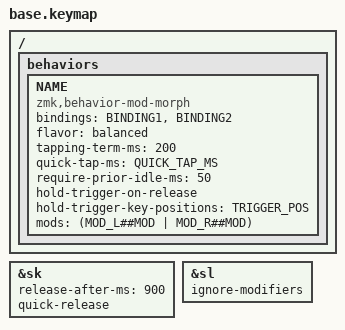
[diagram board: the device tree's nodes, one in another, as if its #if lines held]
#include <behaviors.dtsi>
#include <dt-bindings/zmk/keys.h>
#include <dt-bindings/zmk/rgb.h>
#include <zmk-helpers/helper.h> // Requires zmk-helpers module.

#ifdef CONFIG_WIRELESS
  #include <dt-bindings/zmk/bt.h>
  #include <dt-bindings/zmk/outputs.h>
  #define _BT_SEL_KEYS_                                                        \
      &bt BT_CLR &bt BT_SEL 0 &bt BT_SEL 1 &bt BT_SEL 2 &bt BT_SEL 3
#else
  #define _BT_SEL_KEYS_ &trans &trans &trans &trans &trans
#endif

#define _MEDIA_KEYS_                                                          \
    &kp C_PREVIOUS &kp C_PLAY_PAUSE &kp C_NEXT


#define _VOLUME_KEYS_                                                          \
    &kp C_VOLUME_DOWN &kp C_VOLUME_UP

#define _BRIGHTNESS_KEYS_                                                      \
    &kp C_BRIGHTNESS_DEC &kp C_BRIGHTNESS_INC

#define DEF 0
#define NAV 1
#define NUM 2
#define SYS 3

#define XXX &none
#define ___ &trans

#define KEYS_L LT0 LT1 LT2 LT3 LT4 LM0 LM1 LM2 LM3 LM4 LB0 LB1 LB2 LB3 LB4
#define KEYS_R RT0 RT1 RT2 RT3 RT4 RM0 RM1 RM2 RM3 RM4 RB0 RB1 RB2 RB3 RB4
#define THUMBS LH2 LH1 LH0 RH0 RH1 RH2

#define QUICK_TAP_MS 175

#define MAKE_HRM(NAME, HOLD, TAP, TRIGGER_POS)                                 \
  ZMK_HOLD_TAP(NAME, bindings = <HOLD>, <TAP>; flavor = "balanced";            \
               tapping-term-ms = <200>; quick-tap-ms = <QUICK_TAP_MS>;         \
               require-prior-idle-ms = <50>; hold-trigger-on-release;          \
               hold-trigger-key-positions = <TRIGGER_POS>;)

// Hack: Make HRM combos tap-only (cf, ZMK issue #544).
#define ZMK_COMBO_8(NAME, TAP, POS, LAYERS, COMBO_MS, IDLE_MS, HOLD, SIDE)     \
  MAKE_HRM(hm_combo_##NAME, &kp, TAP, SIDE THUMBS)                             \
  ZMK_COMBO_6(NAME, &hm_combo_##NAME HOLD 0, POS, LAYERS, COMBO_MS, IDLE_MS)

// Define mod-morph with a *single* mod trigger for less repetition.
#define SIMPLE_MORPH(NAME, MOD, BINDING1, BINDING2)                            \
  ZMK_MOD_MORPH(NAME, mods = <(MOD_L##MOD | MOD_R##MOD)>;                      \
                bindings = <BINDING1>, <BINDING2>;)

#define SHIFT_MORPH(NAME, BINDING1, BINDING2)                                  \
  SIMPLE_MORPH(NAME, SFT, BINDING1, BINDING2)

#ifndef ZMK_BASE_LAYER
  #define ZMK_BASE_LAYER(name, LT, RT, LM, RM, LB, RB, LH, RH)                 \
      ZMK_LAYER(name, LT RT LM RM LB RB LH RH)
#endif


&sk {
  release-after-ms = <900>;
  quick-release;
};

&sl { // Allow sticky mods to chord across sticky layers.
  ignore-modifiers;
};

MAKE_HRM(hml, &kp, &kp, KEYS_R THUMBS) // Left-hand HRMs.
MAKE_HRM(hmr, &kp, &kp, KEYS_L THUMBS) // Right-hand HRMs.

#include "morphs.dtsi" // Must be sourced after simple & shift morph.
#include "combos.dtsi" // Must be sourced after HRM-combo hack.

// HRM shortcuts left hand
#define HML_S(key) &hml LSHFT key
#define HML_G(key) &hml LCMD key
#define HML_A(key) &hml LALT key
#define HML_C(key) &hml LCTRL key

// HRM shortcuts right hand
#define HMR_S(key) &hmr RSHFT key
#define HMR_G(key) &hmr RCMD key
#define HMR_A(key) &hmr RALT key
#define HMR_C(key) &hmr LCTRL key

// Misc aliases
#define MEH       LS(LC(LALT))
#define HPR       LS(LC(LG(LALT)))
#define CANCEL    &kp K_CANCEL            // Cancel caps-word & auto-layers.

#define NAV_BSPC  &mt LA(BSPC) BSPC  // Tap: bspc  | Long-tap: delete word bwd.
#define NAV_DEL   &mt LA(DEL)  DEL   // Tap: del   | Long-tap: delete word fwd.

ZMK_CONDITIONAL_LAYER(sys, NAV NUM, SYS) // FN + NUM --> SYS.

ZMK_BASE_LAYER(Base,
//╭─────────────┬─────────────┬─────────────┬─────────────┬─────────────╮ ╭─────────────┬─────────────┬─────────────┬─────────────┬─────────────╮
    &kp Q         &kp W         &kp E         &kp R         &kp T       ,   &kp Y         &kp U         &kp I         &kp O         &kp P       ,
//├─────────────┼─────────────┼─────────────┼─────────────┼─────────────┤ ├─────────────┼─────────────┼─────────────┼─────────────┼─────────────┤
    HML_C(A)      HML_A(S)      HML_G(D)      HML_S(F)      &kp G       ,   &kp H         HMR_S(J)      HMR_G(K)      HMR_A(L)      HMR_C(SQT)  ,
//├─────────────┼─────────────┼─────────────┼─────────────┼─────────────┤ ├─────────────┼─────────────┼─────────────┼─────────────┼─────────────┤
    &kp Z         &kp X        &kp C          &kp V         &kp B       ,   &kp N         &kp M         &comma_semi   &dot_colon    &qmark_emark,
//╰─────────────┼─────────────┴─────────────┼─────────────┼─────────────┤ ├─────────────┼─────────────┼─────────────┴───────────────────────────╯
                               &kp ESC        &mt MEH TAB   &lt NAV SPACE,  &lt NUM BSPC  &mt HPR RET   CANCEL
//                            ╰─────────────┴─────────────┴─────────────╯ ╰─────────────┴─────────────┴─────────────╯
)

ZMK_BASE_LAYER(Nav,
//╭─────────────┬─────────────┬─────────────┬─────────────┬─────────────╮ ╭─────────────┬─────────────┬─────────────┬─────────────┬─────────────╮
    ___           NAV_BSPC      &kp TAB       NAV_DEL       ___         ,   &kp PG_UP     ___           ___           ___           ___         ,
//├─────────────┼─────────────┼─────────────┼─────────────┼─────────────┤ ├─────────────┼─────────────┼─────────────┼─────────────┼─────────────┤
    &sk LCTRL     &sk LALT      &sk LGUI      &sk LSHFT     ___         ,   &kp LEFT      &kp DOWN      &kp UP        &kp RIGHT     &kp RET     ,
//├─────────────┼─────────────┼─────────────┼─────────────┼─────────────┤ ├─────────────┼─────────────┼─────────────┼─────────────┼─────────────┤
    ___           ___           &sk MEH       &sk HPR       ___         ,   &kp PG_DN     ___           ___           ___           ___         ,
//╰─────────────┼─────────────┴─────────────┼─────────────┼─────────────┤ ├─────────────┼─────────────┼─────────────┴───────────────────────────╯
                                ___           ___           ___         ,   ___           ___           ___
//                            ╰─────────────┴─────────────┴─────────────╯ ╰─────────────┴─────────────┴─────────────╯
)


ZMK_BASE_LAYER(Num,
//╭─────────────┬─────────────┬─────────────┬─────────────┬─────────────╮ ╭─────────────┬─────────────┬─────────────┬─────────────┬─────────────╮
    ___           &kp N7        &kp N8        &kp N9        ___         ,   ___           &kp N7        &kp N8        &kp N9        ___         ,
//├─────────────┼─────────────┼─────────────┼─────────────┼─────────────┤ ├─────────────┼─────────────┼─────────────┼─────────────┼─────────────┤
    HML_C(N0)     HML_A(N4)     HML_G(N5)     HML_S(N6)     ___         ,   ___           HMR_S(N4)     HMR_G(N5)     HMR_A(N6)     HMR_C(N0)   ,
//├─────────────┼─────────────┼─────────────┼─────────────┼─────────────┤ ├─────────────┼─────────────┼─────────────┼─────────────┼─────────────┤
    ___           &kp N1        &kp N2        &kp N3        ___         ,   ___           &kp N1        &kp N2        &kp N3        ___         ,
//╰─────────────┼─────────────┴─────────────┼─────────────┼─────────────┤ ├─────────────┼─────────────┼─────────────┴───────────────────────────╯
                                &sk LCTRL     &sk LALT      &sk LGUI    ,   ___           ___           ___
//                            ╰─────────────┴─────────────┴─────────────╯ ╰─────────────┴─────────────┴─────────────╯
)

ZMK_BASE_LAYER(Sys,
//╭─────────────┬─────────────┬─────────────┬─────────────┬─────────────╮ ╭─────────────┬─────────────┬─────────────┬─────────────┬─────────────╮
                               _BT_SEL_KEYS_                            ,   ___                         _MEDIA_KEYS_                ___         ,
//├─────────────┼─────────────┼─────────────┼─────────────┼─────────────┤ ├─────────────┼─────────────┼─────────────┼─────────────┼─────────────┤
    ___           ___           ___           ___           &bootloader ,   &bootloader       _VOLUME_KEYS_           ___           ___         ,
//├─────────────┼─────────────┼─────────────┼─────────────┼─────────────┤ ├─────────────┼─────────────┼─────────────┼─────────────┼─────────────┤
    ___           ___           ___           ___           &sys_reset  ,   &sys_reset      _BRIGHTNESS_KEYS_         ___           ___         ,
//╰─────────────┼─────────────┴─────────────┼─────────────┼─────────────┤ ├─────────────┼─────────────┼─────────────┴───────────────────────────╯
                                ___           ___           ___         ,   ___           ___           ___
//                            ╰─────────────┴─────────────┴─────────────╯ ╰─────────────┴─────────────┴─────────────╯
)

ZMK_BASE_LAYER(Template,
//╭─────────────┬─────────────┬─────────────┬─────────────┬─────────────╮ ╭─────────────┬─────────────┬─────────────┬─────────────┬─────────────╮
    ___           ___           ___           ___           ___         ,   ___           ___           ___           ___           ___         ,
//├─────────────┼─────────────┼─────────────┼─────────────┼─────────────┤ ├─────────────┼─────────────┼─────────────┼─────────────┼─────────────┤
    ___           ___           ___           ___           ___         ,   ___           ___           ___           ___           ___         ,
//├─────────────┼─────────────┼─────────────┼─────────────┼─────────────┤ ├─────────────┼─────────────┼─────────────┼─────────────┼─────────────┤
    ___           ___           ___           ___           ___         ,   ___           ___           ___           ___           ___         ,
//╰─────────────┼─────────────┴─────────────┼─────────────┼─────────────┤ ├─────────────┼─────────────┼─────────────┴───────────────────────────╯
                                ___           ___           ___         ,   ___           ___           ___
//                            ╰─────────────┴─────────────┴─────────────╯ ╰─────────────┴─────────────┴─────────────╯
)

/* vim: set ft=c tw=146: */
